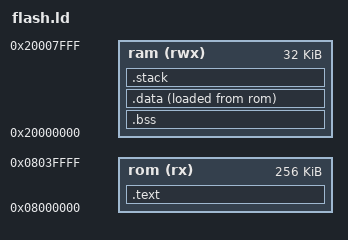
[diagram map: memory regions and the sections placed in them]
ENTRY(Reset_Handler)
MEMORY
{
  rom      (rx)  : ORIGIN = 0x08000000, LENGTH = 0x00040000
  ram      (rwx) : ORIGIN = 0x20000000, LENGTH = 0x00008000
}

STACK_SIZE = 0x2000;

SECTIONS
{
    .text :
    {
        KEEP(*(.vectors .vectors.*))
        *(.text.*)
        *(.rodata.*)
        _etext = . ;
    } > rom

    /* .bss section which is used for uninitialized data */
    .bss (NOLOAD) :
    {
        _sbss = . ;
        *(bss.*)
        *(COMMON)
        _ebss = . ;
    } > ram

    .data :
    {
        _sdata = .;
        *(.data*);
        _edata = .;
    } > ram AT >rom

    /* stack section */
    .stack (NOLOAD):
    {
        . = ALIGN(8);
        _sstack = .;
        . = . + STACK_SIZE;
        . = ALIGN(8);
        _estack = .;
    } > ram

    . = ALIGN(4);
    _end = . ;
}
